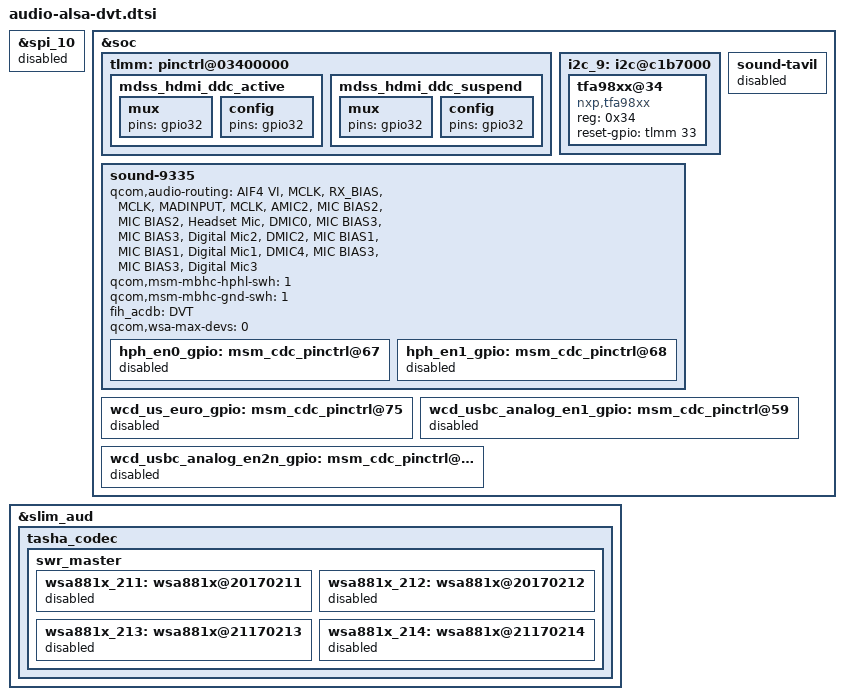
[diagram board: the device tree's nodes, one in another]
&spi_10 {
	status = "disabled";
};

&soc {
	tlmm: pinctrl@03400000 {
		mdss_hdmi_ddc_active: mdss_hdmi_ddc_active {
			mux {
				pins = "gpio32";
			};

			config {
				pins = "gpio32";
			};
		};

		mdss_hdmi_ddc_suspend: mdss_hdmi_ddc_suspend {
			mux {
				pins = "gpio32";
			};

			config {
				pins = "gpio32";
			};
		};
	};

	i2c_9: i2c@c1b7000 { /* BLSP2 QUP3 */
		status = "okay";
		tfa98xx@34 {
			compatible = "nxp,tfa98xx";
			reg = <0x34>;
			reset-gpio = <&tlmm 33 0>;
		};
	};

	sound-9335 {
		qcom,audio-routing =
			"AIF4 VI", "MCLK",
			"RX_BIAS", "MCLK",
			"MADINPUT", "MCLK",
			"AMIC2", "MIC BIAS2",
			"MIC BIAS2", "Headset Mic",
			"DMIC0", "MIC BIAS3",
			"MIC BIAS3", "Digital Mic2",
			"DMIC2", "MIC BIAS1",
			"MIC BIAS1", "Digital Mic1",
			"DMIC4", "MIC BIAS3",
			"MIC BIAS3", "Digital Mic3";

		qcom,msm-mbhc-hphl-swh = <1>;
		qcom,msm-mbhc-gnd-swh = <1>;
		fih_acdb = "DVT";
		/delete-property/ qcom,us-euro-gpios;
		/delete-property/ qcom,hph-en0-gpio;
		/delete-property/ qcom,hph-en1-gpio;

		qcom,wsa-max-devs = <0>;
		/delete-property/ qcom,wsa-devs ;
		/delete-property/ qcom,wsa-aux-dev-prefix ;

		hph_en0_gpio: msm_cdc_pinctrl@67 {
			status = "disabled";
		};

		hph_en1_gpio: msm_cdc_pinctrl@68 {
			status = "disabled";
		};
	};

	sound-tavil {
		status = "disabled";
	};

	wcd_us_euro_gpio: msm_cdc_pinctrl@75 {
		status = "disabled";
	};

	wcd_usbc_analog_en1_gpio: msm_cdc_pinctrl@59 {
		status = "disabled";
	};

	wcd_usbc_analog_en2n_gpio: msm_cdc_pinctrl@60 {
		status = "disabled";
	};
};

&slim_aud {
	tasha_codec {
		swr_master {
			wsa881x_211: wsa881x@20170211 {
				status = "disabled";
			};

			wsa881x_212: wsa881x@20170212 {
				status = "disabled";
			};

			wsa881x_213: wsa881x@21170213 {
				status = "disabled";
			};

			wsa881x_214: wsa881x@21170214 {
				status = "disabled";
			};
		};
	};
};
